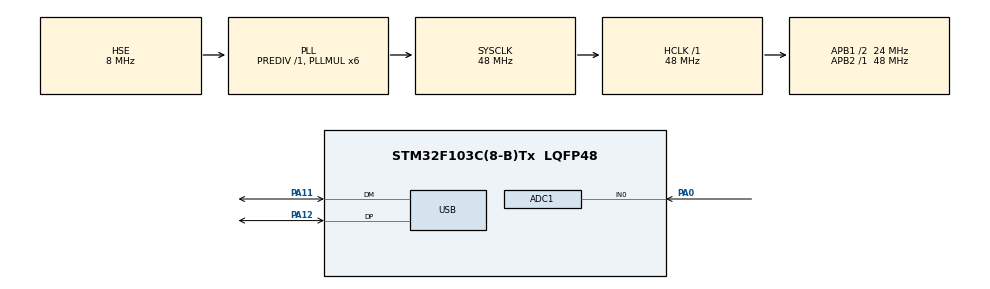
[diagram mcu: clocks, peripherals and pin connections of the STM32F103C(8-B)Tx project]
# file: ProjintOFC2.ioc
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ADC1.Channel-1\#ChannelRegularConversion=ADC_CHANNEL_0
ADC1.NbrOfConversionFlag=1
ADC1.Rank-1\#ChannelRegularConversion=1
ADC1.SamplingTime-1\#ChannelRegularConversion=ADC_SAMPLETIME_1CYCLE_5
ADC1.master=1
Mcu.Family=STM32F1
Mcu.Name=STM32F103C(8-B)Tx
Mcu.Package=LQFP48
NVIC.PriorityGroup=NVIC_PRIORITYGROUP_4
NVIC.USB_LP_CAN1_RX0_IRQn=true\:0\:0\:false\:false\:true\:false\:true
PA0-WKUP.Signal=ADCx_IN0
PA11.Mode=Device
PA11.Signal=USB_DM
PA12.Mode=Device
PA12.Signal=USB_DP
PA13.Mode=Serial_Wire
PA13.Signal=SYS_JTMS-SWDIO
PA14.Mode=Serial_Wire
PA14.Signal=SYS_JTCK-SWCLK
PD0-OSC_IN.Mode=HSE-External-Oscillator
PD0-OSC_IN.Signal=RCC_OSC_IN
PD1-OSC_OUT.Mode=HSE-External-Oscillator
PD1-OSC_OUT.Signal=RCC_OSC_OUT
ProjectManager.HeapSize=0x200
ProjectManager.StackSize=0x400
ProjectManager.TargetToolchain=STM32CubeIDE
RCC.ADCPresc=RCC_ADCPCLK2_DIV4
RCC.AHBFreq_Value=48000000
RCC.APB1CLKDivider=RCC_HCLK_DIV2
RCC.APB1Freq_Value=24000000
RCC.APB1TimFreq_Value=48000000
RCC.APB2Freq_Value=48000000
RCC.APB2TimFreq_Value=48000000
RCC.HCLKFreq_Value=48000000
RCC.PLLMUL=RCC_PLL_MUL6
RCC.PLLSourceVirtual=RCC_PLLSOURCE_HSE
RCC.SYSCLKFreq_VALUE=48000000
RCC.SYSCLKSource=RCC_SYSCLKSOURCE_PLLCLK
RCC.USBFreq_Value=48000000
SH.ADCx_IN0.0=ADC1_IN0,IN0
USB_DEVICE.CLASS_NAME_FS=CDC
USB_DEVICE.VirtualMode=Cdc
USB_DEVICE.VirtualModeFS=Cdc_FS
VP_USB_DEVICE_VS_USB_DEVICE_CDC_FS.Mode=CDC_FS
board=custom

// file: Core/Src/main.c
/* USER CODE BEGIN Header */
/**
  ******************************************************************************
  * @file           : main.c
  * @brief          : Main program body
  ******************************************************************************
  */

/* USER CODE END Header */

#include "main.h"
#include "usb_device.h"
#include "usbd_cdc_if.h"

#include <stdio.h>
#include <stddef.h>
#include <stdint.h>
#include <string.h>

/* USER CODE BEGIN PD */

#define TAMANHO_PACOTE 32

/* USER CODE END PD */

ADC_HandleTypeDef hadc1;

/* USER CODE BEGIN PV */

char pacote[TAMANHO_PACOTE];
uint32_t adc_value = 0;

/* USER CODE END PV */

void SystemClock_Config(void);
static void MX_GPIO_Init(void);
static void MX_ADC1_Init(void);

/* USER CODE BEGIN PFP */

int temp(void)
{
    uint32_t temperatura;

    temperatura = 20 + ((adc_value * 80) / 4095);

    return (int)temperatura;
}

uint8_t xor_checksum(const uint8_t *dados, size_t tamanho)
{
    uint8_t checksum = 0;

    for (size_t i = 0; i < tamanho; i++)
    {
        checksum ^= dados[i];
    }

    return checksum;
}

void Pacote(int temperatura)
{
    uint8_t checksum;

    snprintf(
        pacote,
        TAMANHO_PACOTE,
        "<CQM|T=%d>",
        temperatura
    );

    checksum = xor_checksum(
        (uint8_t *)pacote,
        strlen(pacote)
    );

    snprintf(
        pacote,
        TAMANHO_PACOTE,
        "<CQM|T=%d|X=%02X>\r\n",
        temperatura,
        checksum
    );
}

/* USER CODE END PFP */

int main(void)
{

  HAL_Init();

  SystemClock_Config();

  MX_GPIO_Init();
  MX_ADC1_Init();
  MX_USB_DEVICE_Init();

  /* USER CODE BEGIN 2 */

  HAL_ADC_Start(&hadc1);

  HAL_Delay(1000);

  /* USER CODE END 2 */

  /* Infinite loop */
  while (1)
  {

    /* USER CODE BEGIN 3 */

  while (1)
{
    char teste[] = "TESTE\r\n";

    CDC_Transmit_FS(
        (uint8_t*)teste,
        strlen(teste)
    );

    HAL_Delay(1000);
}

    /* USER CODE END 3 */
  }
}

void SystemClock_Config(void)
{
  RCC_OscInitTypeDef RCC_OscInitStruct = {0};
  RCC_ClkInitTypeDef RCC_ClkInitStruct = {0};
  RCC_PeriphCLKInitTypeDef PeriphClkInit = {0};

  RCC_OscInitStruct.OscillatorType = RCC_OSCILLATORTYPE_HSE;
  RCC_OscInitStruct.HSEState = RCC_HSE_ON;
  RCC_OscInitStruct.HSEPredivValue = RCC_HSE_PREDIV_DIV1;
  RCC_OscInitStruct.HSIState = RCC_HSI_ON;
  RCC_OscInitStruct.PLL.PLLState = RCC_PLL_ON;
  RCC_OscInitStruct.PLL.PLLSource = RCC_PLLSOURCE_HSE;
  RCC_OscInitStruct.PLL.PLLMUL = RCC_PLL_MUL6;

  if (HAL_RCC_OscConfig(&RCC_OscInitStruct) != HAL_OK)
  {
    Error_Handler();
  }

  RCC_ClkInitStruct.ClockType =
      RCC_CLOCKTYPE_HCLK |
      RCC_CLOCKTYPE_SYSCLK |
      RCC_CLOCKTYPE_PCLK1 |
      RCC_CLOCKTYPE_PCLK2;

  RCC_ClkInitStruct.SYSCLKSource = RCC_SYSCLKSOURCE_PLLCLK;
  RCC_ClkInitStruct.AHBCLKDivider = RCC_SYSCLK_DIV1;
  RCC_ClkInitStruct.APB1CLKDivider = RCC_HCLK_DIV2;
  RCC_ClkInitStruct.APB2CLKDivider = RCC_HCLK_DIV1;

  if (HAL_RCC_ClockConfig(
          &RCC_ClkInitStruct,
          FLASH_LATENCY_1) != HAL_OK)
  {
    Error_Handler();
  }

  PeriphClkInit.PeriphClockSelection =
      RCC_PERIPHCLK_ADC |
      RCC_PERIPHCLK_USB;

  PeriphClkInit.AdcClockSelection =
      RCC_ADCPCLK2_DIV4;

  PeriphClkInit.UsbClockSelection =
      RCC_USBCLKSOURCE_PLL;

  if (HAL_RCCEx_PeriphCLKConfig(&PeriphClkInit) != HAL_OK)
  {
    Error_Handler();
  }
}

static void MX_ADC1_Init(void)
{

  ADC_ChannelConfTypeDef sConfig = {0};

  hadc1.Instance = ADC1;

  hadc1.Init.ScanConvMode = ADC_SCAN_DISABLE;
  hadc1.Init.ContinuousConvMode = ENABLE;
  hadc1.Init.DiscontinuousConvMode = DISABLE;
  hadc1.Init.ExternalTrigConv = ADC_SOFTWARE_START;
  hadc1.Init.DataAlign = ADC_DATAALIGN_RIGHT;
  hadc1.Init.NbrOfConversion = 1;

  if (HAL_ADC_Init(&hadc1) != HAL_OK)
  {
    Error_Handler();
  }

  sConfig.Channel = ADC_CHANNEL_0;
  sConfig.Rank = ADC_REGULAR_RANK_1;
  sConfig.SamplingTime = ADC_SAMPLETIME_55CYCLES_5;

  if (HAL_ADC_ConfigChannel(&hadc1, &sConfig) != HAL_OK)
  {
    Error_Handler();
  }

}

static void MX_GPIO_Init(void)
{
  __HAL_RCC_GPIOD_CLK_ENABLE();
  __HAL_RCC_GPIOA_CLK_ENABLE();
}

void Error_Handler(void)
{
  __disable_irq();
  while (1)
  {
  }
}

/************************ (C) COPYRIGHT STMicroelectronics *****END OF FILE****/
